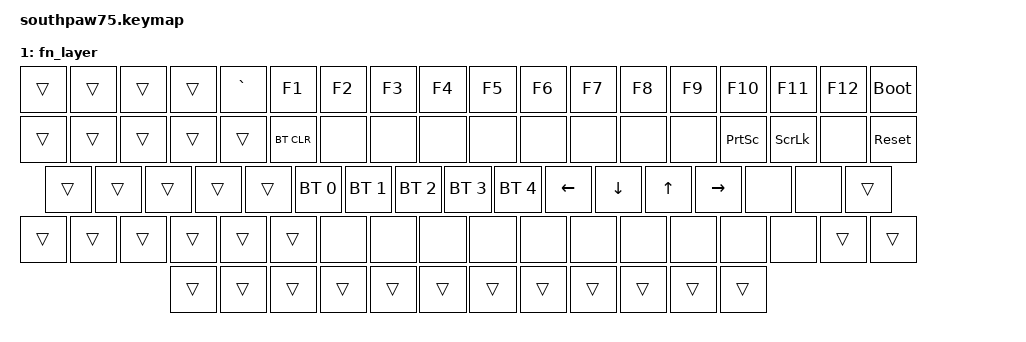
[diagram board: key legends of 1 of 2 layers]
/*
 * Copyright (c) 2020 The ZMK Contributors
 *
 * SPDX-License-Identifier: MIT
 */

#include <behaviors.dtsi>
#include <dt-bindings/zmk/keys.h>
#include <dt-bindings/zmk/bt.h>

/ {
    keymap0: keymap {
        compatible = "zmk,keymap";

        default_layer {
// ------------------------------------------------------------------------------------------------------------------
// | NUM |  /  |  *  |  -  | ESC |  1  |  2  |  3  |  4  |  5  |  6  |  7  |  8  |  9  |  0  |  -  |  =  |   BKSP   |
// |  7  |  8  |  9  |     | TAB  |  Q  |  W  |  E  |  R  |  T  |  Y  |  U  |  I  |  O  |  P  |  [  |  ]  |    \    |
// |  4  |  5  |  6  | ENT | CAPS  |  A  |  S  |  D  |  F  |  G  |  H  |  J  |  K  |  L  |  ;  |  '  |     ENTER    |
// |  1  |  2  |  3  |     |  SHIFT  |  Z  |  X  |  C  |  V  |  B  |  N  |  M  |  ,  |  .  |  /  |  SHIFT   | MO(2) |
// |     0     |  .  |     |  CTL  |  WIN  |  ALT  |             SPACE              |  ALT  | MO(1) |  WIN  | CTRL  |
// ------------------------------------------------------------------------------------------------------------------
            bindings = <
                &kp KP_NLCK &kp KP_DIVIDE &kp KP_MULTIPLY &kp KP_MINUS   &kp ESC         &kp N1 &kp N2 &kp N3 &kp N4 &kp N5 &kp N6 &kp N7 &kp   N8  &kp  N9 &kp  N0  &kp MINUS &kp EQUAL &kp BSPC
                &kp KP_N7   &kp KP_N8     &kp KP_N9        &kp KP_PLUS    &kp TAB          &kp Q  &kp W  &kp E  &kp R  &kp T  &kp Y  &kp U  &kp   I   &kp  O  &kp   P  &kp LBKT &kp RBKT  &kp BSLH
                &kp KP_N4   &kp KP_N5     &kp KP_N6                       &kp CLCK          &kp A  &kp S  &kp D  &kp F  &kp G  &kp H  &kp J  &kp   K   &kp  L  &kp SEMI &kp SQT           &kp RET
                &kp KP_N1   &kp KP_N2     &kp KP_N3        &kp KP_ENTER   &kp LSHFT &kp NUBS &kp Z  &kp X  &kp C  &kp V  &kp B  &kp N  &kp M  &kp COMMA &kp DOT &kp FSLH        &kp RSHFT &mo  2
                    &kp KP_N0             &kp KP_DOT                     &kp LCTRL &kp LGUI &kp LALT               &kp SPACE                 &kp  RALT  &mo  1  &kp  RGUI  &kp  RCTRL
            >;
        };

        fn_layer {
            bindings = <
                &trans      &trans        &trans          &trans         &kp GRAVE  &kp F1     &kp F2     &kp F3     &kp F4     &kp F5     &kp F6     &kp F7     &kp F8     &kp F9     &kp F10    &kp F11    &kp F12    &bootloader
                &trans      &trans        &trans          &trans         &trans         &bt BT_CLR &none      &none      &none      &none      &none      &none      &none      &none      &kp PSCRN  &kp SLCK   &none      &sys_reset
                &trans      &trans        &trans          &trans         &trans           &bt BT_SEL 0 &bt BT_SEL 1 &bt BT_SEL 2 &bt BT_SEL 3 &bt BT_SEL 4 &kp LEFT   &kp DOWN   &kp UP   &kp RIGHT   &none      &none      &trans
                &trans      &trans        &trans          &trans         &trans &trans         &none      &none      &none      &none      &none      &none      &none      &none      &none      &none          &trans     &trans
                &trans      &trans        &trans          &trans         &trans       &trans       &trans                                      &trans                                      &trans     &trans     &trans     &trans
            >;
        };
    };
};
